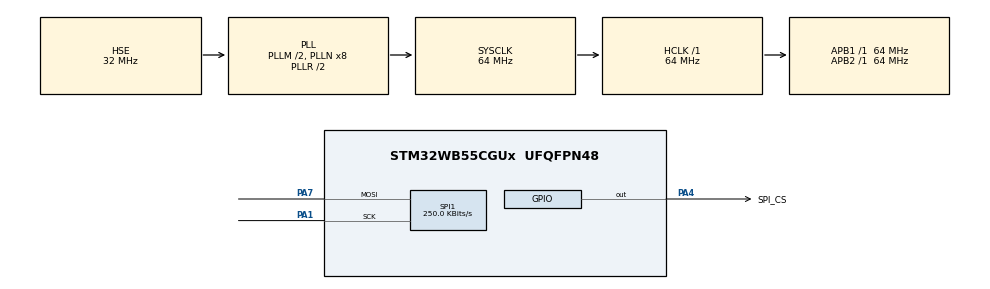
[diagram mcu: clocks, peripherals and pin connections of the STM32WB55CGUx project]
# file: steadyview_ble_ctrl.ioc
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FREERTOS.INCLUDE_xTaskGetCurrentTaskHandle=1
FREERTOS.Tasks01=defaultTask,24,1024,StartDefaultTask,Default,NULL,Dynamic,NULL,NULL
FREERTOS.configMINIMAL_STACK_SIZE=128
FREERTOS.configTOTAL_HEAP_SIZE=20480
FREERTOS.configUSE_TICKLESS_IDLE=0
Mcu.Family=STM32WB
Mcu.Name=STM32WB55CGUx
Mcu.Package=UFQFPN48
NVIC.HSEM_IRQn=true\:5\:0\:false\:false\:true\:false\:false\:true\:true
NVIC.IPCC_C1_RX_IRQn=true\:5\:0\:false\:false\:true\:true\:true\:true\:true
NVIC.IPCC_C1_TX_IRQn=true\:5\:0\:false\:false\:true\:true\:true\:true\:true
NVIC.PriorityGroup=NVIC_PRIORITYGROUP_4
NVIC.RTC_WKUP_IRQn=true\:5\:0\:false\:false\:true\:true\:true\:true\:true
NVIC.TIM1_TRG_COM_TIM17_IRQn=true\:15\:0\:false\:false\:true\:false\:false\:true\:true
NVIC.TimeBase=TIM1_TRG_COM_TIM17_IRQn
NVIC.TimeBaseIP=TIM17
OSC_IN.Mode=HSE-External-Oscillator
OSC_IN.Signal=RCC_OSC_IN
OSC_OUT.Mode=HSE-External-Oscillator
OSC_OUT.Signal=RCC_OSC_OUT
PA1.Mode=Half_Duplex_Master
PA1.Signal=SPI1_SCK
PA13.Mode=Serial_Wire
PA13.Signal=SYS_JTMS-SWDIO
PA14.Mode=Serial_Wire
PA14.Signal=SYS_JTCK-SWCLK
PA4.GPIO_Label=SPI_CS
PA4.PinState=GPIO_PIN_SET
PA4.Signal=GPIO_Output
PA7.Mode=Half_Duplex_Master
PA7.Signal=SPI1_MOSI
ProjectManager.HeapSize=0x400
ProjectManager.StackSize=0x1000
ProjectManager.TargetToolchain=STM32CubeIDE
RCC.ADCFreq_Value=64000000
RCC.AHB2CLKDivider=RCC_SYSCLK_DIV2
RCC.AHBFreq_Value=64000000
RCC.APB1Freq_Value=64000000
RCC.APB1TimFreq_Value=64000000
RCC.APB2Freq_Value=64000000
RCC.APB2TimFreq_Value=64000000
RCC.APB3Freq_Value=16000000
RCC.CK48CLockSelection=RCC_USBCLKSOURCE_HSI48
RCC.CortexFreq_Value=64000000
RCC.HCLKFreq_Value=64000000
RCC.HSE_VALUE=32000000
RCC.HSI48_VALUE=48000000
RCC.HSI_VALUE=16000000
RCC.LSE_Drive_Capability=RCC_LSEDRIVE_LOW
RCC.PLLM=RCC_PLLM_DIV2
RCC.PLLN=8
RCC.PLLR=RCC_PLLR_DIV2
RCC.PLLSourceVirtual=RCC_PLLSOURCE_HSE
RCC.RFWKPClockSelection=RCC_RFWKPCLKSOURCE_HSE_DIV1024
RCC.RNGCLockSelection=RCC_RNGCLKSOURCE_LSI
RCC.RTCClockSelection=RCC_RTCCLKSOURCE_LSI
RCC.SMPSCLockSelection=RCC_SMPSCLKSOURCE_HSI
RCC.SMPSCLockSelectionVirtual=RCC_SMPSCLKSOURCE_HSI
RCC.SMPSDivider=2
RCC.SYSCLKFreq_VALUE=64000000
RCC.SYSCLKSource=RCC_SYSCLKSOURCE_PLLCLK
RCC.USBFreq_Value=48000000
RCC.VCOOutputFreq_Value=128000000
RF1.Mode=RF1_Activate
RF1.Signal=RF_RF1
RTC.AsynchPrediv=15
RTC.SynchPrediv=1999
SPI1.BaudRatePrescaler=SPI_BAUDRATEPRESCALER_256
SPI1.CLKPhase=SPI_PHASE_1EDGE
SPI1.CLKPolarity=SPI_POLARITY_LOW
SPI1.CalculateBaudRate=250.0 KBits/s
SPI1.DataSize=SPI_DATASIZE_5BIT
SPI1.Direction=SPI_DIRECTION_1LINE
SPI1.FirstBit=SPI_FIRSTBIT_LSB
SPI1.Mode=SPI_MODE_MASTER
SPI1.NSS=SPI_NSS_SOFT
STM32_WPAN.BLE_ADDR_TYPE=PUBLIC_ADDR
STM32_WPAN.BLE_APPLICATION_TYPE=BLE_SERVER_PROFILE
STM32_WPAN.BLE_CFG_DIS_FIRMWARE_REVISION_STRING=0
STM32_WPAN.BLE_CFG_DIS_HARDWARE_REVISION_STRING=0
STM32_WPAN.BLE_CFG_DIS_IEEE_CERTIFICATION=0
STM32_WPAN.BLE_CFG_DIS_MANUFACTURER_NAME_STRING=1
STM32_WPAN.BLE_CFG_DIS_MODEL_NUMBER_STRING=0
STM32_WPAN.BLE_CFG_DIS_PNP_ID=0
STM32_WPAN.BLE_CFG_DIS_SERIAL_NUMBER_STRING=0
STM32_WPAN.BLE_CFG_DIS_SOFTWARE_REVISION_STRING=0
STM32_WPAN.BLE_CFG_DIS_SYSTEM_ID=0
STM32_WPAN.BLE_CFG_HRS_BODY_SENSOR_LOCATION_CHAR=1
STM32_WPAN.BLE_CFG_HRS_ENERGY_EXPENDED_INFO_FLAG=1
STM32_WPAN.BLE_CFG_HRS_ENERGY_RR_INTERVAL_FLAG=1
STM32_WPAN.BLE_DBG_DIS_EN=1
STM32_WPAN.BLE_DBG_HRS_EN=1
STM32_WPAN.BLE_DBG_SVCCTL_EN=1
STM32_WPAN.BT_SIG_HEART_RATE_SENSOR=Disabled
STM32_WPAN.CFG_ADV_BD_ADDRESS=0x7257acd87a6c
STM32_WPAN.CFG_BLE_LS_SOURCE=SHCI_C2_BLE_INIT_CFG_BLE_LS_CLK_HSE_1024
STM32_WPAN.CFG_BLE_MAX_CONN_EVENT_LENGTH=0xFFFFFFFF
STM32_WPAN.CFG_BLE_MAX_TX_POWER=6
STM32_WPAN.CFG_BLE_MIN_TX_POWER=-40
STM32_WPAN.CFG_DEBUGGER_SUPPORTED=0
STM32_WPAN.CFG_DEBUG_APP_TRACE=0
STM32_WPAN.CFG_DEBUG_BLE_TRACE=0
STM32_WPAN.CFG_DEBUG_TRACE_UART=hw_uart1
STM32_WPAN.CFG_FAST_CONN_ADV_INTERVAL_MAX=100
STM32_WPAN.CFG_FAST_CONN_ADV_INTERVAL_MAX_HEXA=0xa0
STM32_WPAN.CFG_FAST_CONN_ADV_INTERVAL_MIN=80
STM32_WPAN.CFG_HW_LPUART1_DMA_TX_SUPPORTED=0
STM32_WPAN.CFG_HW_LPUART1_ENABLED=0
STM32_WPAN.CFG_HW_RESET_BY_FW=0
STM32_WPAN.CFG_HW_TS_MAX_NBR_CONCURRENT_TIMER=6
STM32_WPAN.CFG_HW_TS_NVIC_RTC_WAKEUP_IT_PREEMPTPRIO=3
STM32_WPAN.CFG_HW_TS_NVIC_RTC_WAKEUP_IT_SUBPRIO=0
STM32_WPAN.CFG_HW_TS_USE_PRIMASK_AS_CRITICAL_SECTION=1
STM32_WPAN.CFG_HW_USART1_ENABLED=0
STM32_WPAN.CFG_IO_CAPABILITY=CFG_IO_CAPABILITY_DISPLAY_YES_NO
STM32_WPAN.CFG_LPM_SUPPORTED=0
STM32_WPAN.CFG_LP_CONN_ADV_INTERVAL_MAX=2500
STM32_WPAN.CFG_LP_CONN_ADV_INTERVAL_MAX_HEXA=0xfa0
STM32_WPAN.CFG_LP_CONN_ADV_INTERVAL_MIN=1000
STM32_WPAN.CFG_MITM_PROTECTION=CFG_MITM_PROTECTION_REQUIRED
STM32_WPAN.CFG_RTCCLK_DIVIDER_CONF=16
STM32_WPAN.CFG_USE_SMPS=0
STM32_WPAN.DBG_TRACE_UART_CFG=hw_uart1
STM32_WPAN.L2CAP_REQUEST_NEW_CONN_PARAM=1
STM32_WPAN.LOCAL_NAME=SteadyView
STM32_WPAN.LOCAL_NAME_FORMATTED='S','t','e','a','d','y','V','i','e','w'
STM32_WPAN.P2P_SERVER_NUMBER=P2P_SERVER1
STM32_WPAN.STATIC_RANDOM_ADDRESS=0x112233445566
VP_FREERTOS_VS_CMSIS_V2.Mode=CMSIS_V2
VP_HSEM_VS_HSEM.Mode=HSEM_Activate
VP_IPCC_VS_IPCC.Mode=IPCC_Activate
VP_RNG_VS_RNG.Mode=RNG_Activate
VP_RTC_VS_RTC_Activate.Mode=RTC_Enabled
VP_RTC_VS_RTC_WakeUp_intern.Mode=WakeUp
VP_STM32_WPAN_VS_BLE_HOST.Mode=STM32_WPAN_Enabled
VP_SYS_VS_tim17.Mode=TIM17
VP_TINY_LPM_VS_TINY_LPM.Mode=TINY_LPM_Enabled
board=custom

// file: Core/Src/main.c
/* USER CODE BEGIN Header */
/**
  ******************************************************************************
 * @file    main.c
 * @author  MCD Application Team
 * @brief   BLE application with BLE core
 *
  ******************************************************************************
  * @attention
  *
  * Copyright (c) 2019-2021 STMicroelectronics.
  * All rights reserved.
  *
  * This software is licensed under terms that can be found in the LICENSE file
  * in the root directory of this software component.
  * If no LICENSE file comes with this software, it is provided AS-IS.
  *
  ******************************************************************************
  @verbatim
  ==============================================================================
                    ##### IMPORTANT NOTE #####
  ==============================================================================

  This application requests having the stm32wb5x_BLE_Stack_full_fw.bin binary
  flashed on the Wireless Coprocessor.
  If it is not the case, you need to use STM32CubeProgrammer to load the appropriate
  binary.

  All available binaries are located under following directory:
  /Wireless

  Refer to UM2237 to learn how to use/install STM32CubeProgrammer.
  Refer to /Wireless/ReleaseNote.html for the
  detailed procedure to change the Wireless Coprocessor binary.

  @endverbatim
  ******************************************************************************
  */
/* USER CODE END Header */
#include "main.h"
#include "spi.h"
#include "control_app.h"
#include "cmsis_os2.h"
#include "FreeRTOS.h"

IPCC_HandleTypeDef hipcc;

RNG_HandleTypeDef hrng;

RTC_HandleTypeDef hrtc;

/* Definitions for defaultTask */
osThreadId_t defaultTaskHandle;
const osThreadAttr_t defaultTask_attributes = {
  .name = "defaultTask",
  .priority = (osPriority_t) osPriorityNormal,
  .stack_size = 1024 * 4
};

void SystemClock_Config(void);
void PeriphCommonClock_Config(void);
static void MX_GPIO_Init(void);

static void MX_RTC_Init(void);
static void MX_IPCC_Init(void);
static void MX_RNG_Init(void);
static void MX_RF_Init(void);
void StartDefaultTask(void *argument);

int main(void)
{

  /* MCU Configuration--------------------------------------------------------*/

  /* Reset of all peripherals, Initializes the Flash interface and the Systick. */
  HAL_Init();
  /* Config code for STM32_WPAN (HSE Tuning must be done before system clock configuration) */
  MX_APPE_Config();

  /* Configure the system clock */
  SystemClock_Config();

/* Configure the peripherals common clocks */
  PeriphCommonClock_Config();

  /* IPCC initialisation */
  MX_IPCC_Init();

  /* Initialize all configured peripherals */
  MX_GPIO_Init();
  MX_SPI1_Init();
  MX_RTC_Init();
  MX_RNG_Init();
  MX_RF_Init();

  /* Init scheduler */
  osKernelInitialize();
  SPI1_RTOS_Init();
  ControlApp_Init();

  /* Create the thread(s) */
  /* creation of defaultTask */
  defaultTaskHandle = osThreadNew(StartDefaultTask, NULL, &defaultTask_attributes);

  /* Init code for STM32_WPAN */
  MX_APPE_Init();

  /* Start scheduler */
  osKernelStart();

  /* We should never get here as control is now taken by the scheduler */

  /* Infinite loop */
	while(1)
	{

  }
}

void SystemClock_Config(void)
{
  RCC_OscInitTypeDef RCC_OscInitStruct = {0};
  RCC_ClkInitTypeDef RCC_ClkInitStruct = {0};

  /** Configure LSE Drive Capability
  */
  HAL_PWR_EnableBkUpAccess();
  __HAL_RCC_LSEDRIVE_CONFIG(RCC_LSEDRIVE_LOW);

  /** Configure the main internal regulator output voltage
  */
  __HAL_PWR_VOLTAGESCALING_CONFIG(PWR_REGULATOR_VOLTAGE_SCALE1);

  /** Initializes the RCC Oscillators according to the specified parameters
  * in the RCC_OscInitTypeDef structure.
  */
  RCC_OscInitStruct.OscillatorType = RCC_OSCILLATORTYPE_HSI48|RCC_OSCILLATORTYPE_HSI
                              |RCC_OSCILLATORTYPE_HSE|RCC_OSCILLATORTYPE_LSI1;
  RCC_OscInitStruct.HSEState = RCC_HSE_ON;
  RCC_OscInitStruct.LSIState = RCC_LSI_ON;
  RCC_OscInitStruct.HSIState = RCC_HSI_ON;
  RCC_OscInitStruct.HSI48State = RCC_HSI48_ON;
  RCC_OscInitStruct.HSICalibrationValue = RCC_HSICALIBRATION_DEFAULT;
  RCC_OscInitStruct.PLL.PLLState = RCC_PLL_ON;
  RCC_OscInitStruct.PLL.PLLSource = RCC_PLLSOURCE_HSE;
  RCC_OscInitStruct.PLL.PLLM = RCC_PLLM_DIV2;
  RCC_OscInitStruct.PLL.PLLN = 8;
  RCC_OscInitStruct.PLL.PLLP = RCC_PLLP_DIV2;
  RCC_OscInitStruct.PLL.PLLQ = RCC_PLLQ_DIV2;
  RCC_OscInitStruct.PLL.PLLR = RCC_PLLR_DIV2;
  if (HAL_RCC_OscConfig(&RCC_OscInitStruct) != HAL_OK)
  {
    Error_Handler();
  }

  /** Configure the SYSCLKSource, HCLK, PCLK1 and PCLK2 clocks dividers
  */
  RCC_ClkInitStruct.ClockType = RCC_CLOCKTYPE_HCLK4|RCC_CLOCKTYPE_HCLK2
                              |RCC_CLOCKTYPE_HCLK|RCC_CLOCKTYPE_SYSCLK
                              |RCC_CLOCKTYPE_PCLK1|RCC_CLOCKTYPE_PCLK2;
  RCC_ClkInitStruct.SYSCLKSource = RCC_SYSCLKSOURCE_PLLCLK;
  RCC_ClkInitStruct.AHBCLKDivider = RCC_SYSCLK_DIV1;
  RCC_ClkInitStruct.APB1CLKDivider = RCC_HCLK_DIV1;
  RCC_ClkInitStruct.APB2CLKDivider = RCC_HCLK_DIV1;
  RCC_ClkInitStruct.AHBCLK2Divider = RCC_SYSCLK_DIV2;
  RCC_ClkInitStruct.AHBCLK4Divider = RCC_SYSCLK_DIV1;

  if (HAL_RCC_ClockConfig(&RCC_ClkInitStruct, FLASH_LATENCY_3) != HAL_OK)
  {
    Error_Handler();
  }
}

void PeriphCommonClock_Config(void)
{
  RCC_PeriphCLKInitTypeDef PeriphClkInitStruct = {0};

  /** Initializes the peripherals clock
  */
  PeriphClkInitStruct.PeriphClockSelection = RCC_PERIPHCLK_SMPS|RCC_PERIPHCLK_RFWAKEUP;
  PeriphClkInitStruct.RFWakeUpClockSelection = RCC_RFWKPCLKSOURCE_HSE_DIV1024;
  PeriphClkInitStruct.SmpsClockSelection = RCC_SMPSCLKSOURCE_HSI;
  PeriphClkInitStruct.SmpsDivSelection = RCC_SMPSCLKDIV_RANGE1;

  if (HAL_RCCEx_PeriphCLKConfig(&PeriphClkInitStruct) != HAL_OK)
  {
    Error_Handler();
  }
}

static void MX_IPCC_Init(void)
{

  hipcc.Instance = IPCC;
  if (HAL_IPCC_Init(&hipcc) != HAL_OK)
  {
    Error_Handler();
  }

}

static void MX_RF_Init(void)
{

}

static void MX_RNG_Init(void)
{

  hrng.Instance = RNG;
  hrng.Init.ClockErrorDetection = RNG_CED_DISABLE;
  if (HAL_RNG_Init(&hrng) != HAL_OK)
  {
    Error_Handler();
  }

}

static void MX_RTC_Init(void)
{

  /** Initialize RTC Only
  */
  hrtc.Instance = RTC;
  hrtc.Init.HourFormat = RTC_HOURFORMAT_24;
  hrtc.Init.AsynchPrediv = CFG_RTC_ASYNCH_PRESCALER;
  hrtc.Init.SynchPrediv = CFG_RTC_SYNCH_PRESCALER;
  hrtc.Init.OutPut = RTC_OUTPUT_DISABLE;
  hrtc.Init.OutPutPolarity = RTC_OUTPUT_POLARITY_HIGH;
  hrtc.Init.OutPutType = RTC_OUTPUT_TYPE_OPENDRAIN;
  hrtc.Init.OutPutRemap = RTC_OUTPUT_REMAP_NONE;
  if (HAL_RTC_Init(&hrtc) != HAL_OK)
  {
    Error_Handler();
  }

  /** Enable the WakeUp
  */
  if (HAL_RTCEx_SetWakeUpTimer_IT(&hrtc, 0, RTC_WAKEUPCLOCK_RTCCLK_DIV16) != HAL_OK)
  {
    Error_Handler();
  }
  /* Set an initial calendar once; preserve it across MCU resets. */
  if (HAL_RTCEx_BKUPRead(&hrtc, RTC_BKP_DR1) != 0x5356U)
  {
    RTC_TimeTypeDef time = {0};
    RTC_DateTypeDef date = {0};
    date.WeekDay = RTC_WEEKDAY_SATURDAY;
    date.Month = RTC_MONTH_JANUARY;
    date.Date = 1;
    date.Year = 0;
    if (HAL_RTC_SetTime(&hrtc, &time, RTC_FORMAT_BIN) != HAL_OK ||
        HAL_RTC_SetDate(&hrtc, &date, RTC_FORMAT_BIN) != HAL_OK) Error_Handler();
    HAL_RTCEx_BKUPWrite(&hrtc, RTC_BKP_DR1, 0x5356U);
  }

}

static void MX_GPIO_Init(void)
{

  /* GPIO Ports Clock Enable */
  __HAL_RCC_GPIOC_CLK_ENABLE();
  __HAL_RCC_GPIOA_CLK_ENABLE();
  __HAL_RCC_GPIOB_CLK_ENABLE();

}

void StartDefaultTask(void *argument)
{
  (void)argument;
  /* USER CODE BEGIN 5 */
  ControlApp_Run();
  /* USER CODE END 5 */
}

void HAL_TIM_PeriodElapsedCallback(TIM_HandleTypeDef *htim)
{
  if (htim->Instance == TIM17)
  {
    HAL_IncTick();
  }
}

void Error_Handler(void)
{
  __disable_irq();
  while (1) {}
}
